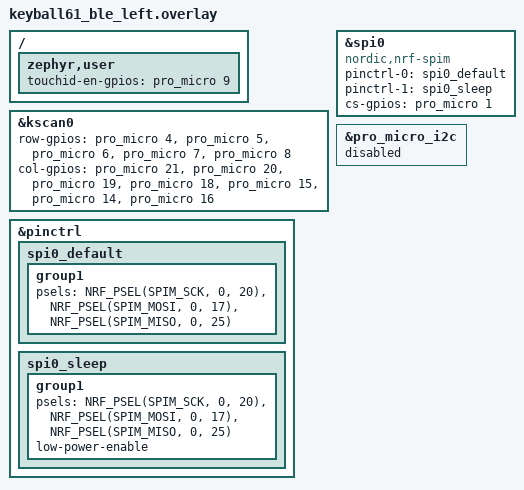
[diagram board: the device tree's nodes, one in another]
/*
 * Copyright (c) 2020 ZMK Contributors
 *
 * SPDX-License-Identifier: MIT
 */

#include "keyball61_ble.dtsi"

/ {
    zephyr,user {
        /*
         * Touch ID 5 V boost (TPS61023 U2 on the keyball61-ble left board):
         * its EN pin is on pm9 (P1.06), the controller pin nearest the boost.
         * R3 (1 M) holds EN low until the firmware drives it high. Not pm1 as
         * on the bought board: pm1 is the nice!view's CS here.
         */
        touchid-en-gpios = <&pro_micro 9 GPIO_ACTIVE_HIGH>;
    };
};

&kscan0 {
	row-gpios
        = <&pro_micro 4 (GPIO_ACTIVE_HIGH | GPIO_PULL_DOWN)>
        , <&pro_micro 5 (GPIO_ACTIVE_HIGH | GPIO_PULL_DOWN)>
        , <&pro_micro 6 (GPIO_ACTIVE_HIGH | GPIO_PULL_DOWN)>
        , <&pro_micro 7 (GPIO_ACTIVE_HIGH | GPIO_PULL_DOWN)>
        , <&pro_micro 8 (GPIO_ACTIVE_HIGH | GPIO_PULL_DOWN)>
        ;
    col-gpios
        = <&pro_micro 21 GPIO_ACTIVE_HIGH>
        , <&pro_micro 20 GPIO_ACTIVE_HIGH>
        , <&pro_micro 19 GPIO_ACTIVE_HIGH>
	    , <&pro_micro 18 GPIO_ACTIVE_HIGH>
		, <&pro_micro 15 GPIO_ACTIVE_HIGH>
		, <&pro_micro 14 GPIO_ACTIVE_HIGH>
		, <&pro_micro 16 GPIO_ACTIVE_HIGH>
		;
};

/*
 * nice!view on SPI0: MOSI pm2 (P0.17), SCK pm3 (P0.20), CS pm1 (P0.06).
 * Same pins as ZMK's nice_view_adapter; defined here so both halves build
 * with just the nice_view shield. The display has no MISO; P0.25 is unused.
 */
&pinctrl {
    spi0_default: spi0_default {
        group1 {
            psels = <NRF_PSEL(SPIM_SCK, 0, 20)>,
                <NRF_PSEL(SPIM_MOSI, 0, 17)>,
                <NRF_PSEL(SPIM_MISO, 0, 25)>;
        };
    };

    spi0_sleep: spi0_sleep {
        group1 {
            psels = <NRF_PSEL(SPIM_SCK, 0, 20)>,
                <NRF_PSEL(SPIM_MOSI, 0, 17)>,
                <NRF_PSEL(SPIM_MISO, 0, 25)>;
            low-power-enable;
        };
    };
};

nice_view_spi: &spi0 {
    compatible = "nordic,nrf-spim";
    pinctrl-0 = <&spi0_default>;
    pinctrl-1 = <&spi0_sleep>;
    pinctrl-names = "default", "sleep";
    cs-gpios = <&pro_micro 1 GPIO_ACTIVE_HIGH>;
};

/* SPI0 and I2C0 share one peripheral on the nRF52840. */
&pro_micro_i2c {
    status = "disabled";
};
